# PIC18F55Q24 register map
Vendor: Microchip
Registers are 8-bit, read-write, reset 0x0 unless marked. A register's access mark holds for its fields unless they carry their own. Addresses are absolute, and some are shared; only a register's first bit layout is shown; [hi:lo] are bit positions; {n}, {i} and the like mark numbered series; 'fields as' and 'values as' point back to an identical list.

## DOS_xxxxx_pps_mid_v2_output_8bit
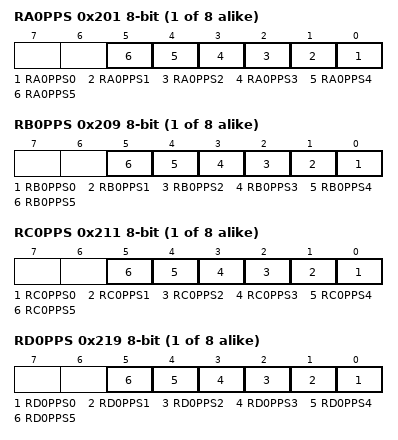
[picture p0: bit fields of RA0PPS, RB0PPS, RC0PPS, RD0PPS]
{0x201+i} RA{i}PPS (i=0..7)
  [n] RA{i}PPS{n} (n=0..5)
{0x209+i} RB{i}PPS (i=0..7)
  [n] RB{i}PPS{n} (n=0..5)
{0x211+i} RC{i}PPS (i=0..7)
  [n] RC{i}PPS{n} (n=0..5)
{0x219+i} RD{i}PPS (i=0..7)
  [n] RD{i}PPS{n} (n=0..5)
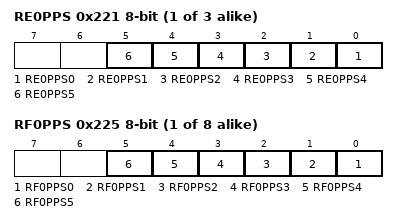
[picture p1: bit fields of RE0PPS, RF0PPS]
{0x221+i} RE{i}PPS (i=0..2)
  [n] RE{i}PPS{n} (n=0..5)
{0x225+i} RF{i}PPS (i=0..7)
  [n] RF{i}PPS{n} (n=0..5)

## DOS_xxxx_pps_mid
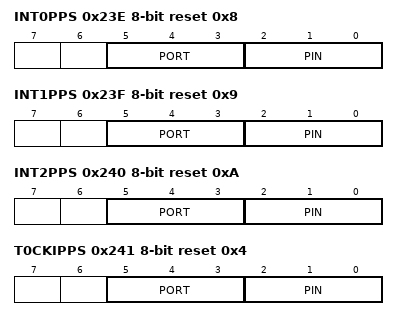
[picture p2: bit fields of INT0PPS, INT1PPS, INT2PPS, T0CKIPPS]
0x23E INT0PPS reset 0x8
  [5:3] PORT, [2:0] PIN
0x23F INT1PPS reset 0x9
  [5:3] PORT, [2:0] PIN
0x240 INT2PPS reset 0xA
  [5:3] PORT, [2:0] PIN
0x241 T0CKIPPS reset 0x4
  [5:3] PORT, [2:0] PIN
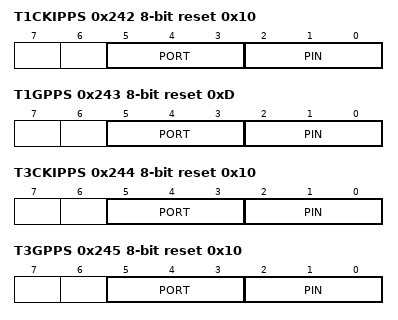
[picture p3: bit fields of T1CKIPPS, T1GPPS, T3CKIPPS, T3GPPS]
0x242 T1CKIPPS reset 0x10
  [5:3] PORT, [2:0] PIN
0x243 T1GPPS reset 0xD
  [5:3] PORT, [2:0] PIN
0x244 T3CKIPPS reset 0x10
  [5:3] PORT, [2:0] PIN
0x245 T3GPPS reset 0x10
  [5:3] PORT, [2:0] PIN
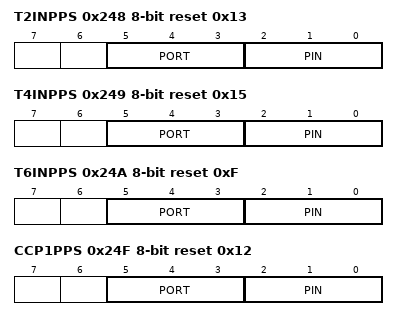
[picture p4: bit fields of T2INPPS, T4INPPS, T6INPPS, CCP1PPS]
0x248 T2INPPS reset 0x13
  [5:3] PORT, [2:0] PIN
0x249 T4INPPS reset 0x15
  [5:3] PORT, [2:0] PIN
0x24A T6INPPS reset 0xF
  [5:3] PORT, [2:0] PIN
0x24F CCP1PPS reset 0x12
  [5:3] PORT, [2:0] PIN
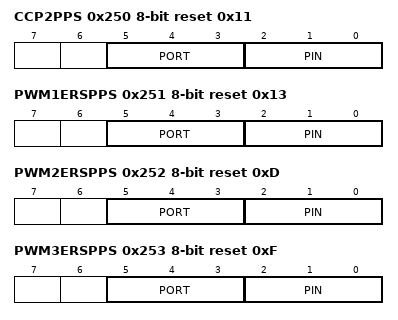
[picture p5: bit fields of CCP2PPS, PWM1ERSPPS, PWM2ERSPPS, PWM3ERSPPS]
0x250 CCP2PPS reset 0x11
  [5:3] PORT, [2:0] PIN
0x251 PWM1ERSPPS reset 0x13
  [5:3] PORT, [2:0] PIN
0x252 PWM2ERSPPS reset 0xD
  [5:3] PORT, [2:0] PIN
0x253 PWM3ERSPPS reset 0xF
  [5:3] PORT, [2:0] PIN
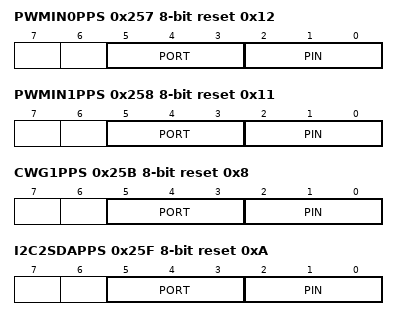
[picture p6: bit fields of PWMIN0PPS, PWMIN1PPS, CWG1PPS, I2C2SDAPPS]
0x257 PWMIN0PPS reset 0x12
  [5:3] PORT, [2:0] PIN
0x258 PWMIN1PPS reset 0x11
  [5:3] PORT, [2:0] PIN
0x25B CWG1PPS reset 0x8
  [5:3] PORT, [2:0] PIN
0x25F I2C2SDAPPS reset 0xA
  [5:3] PORT, [2:0] PIN
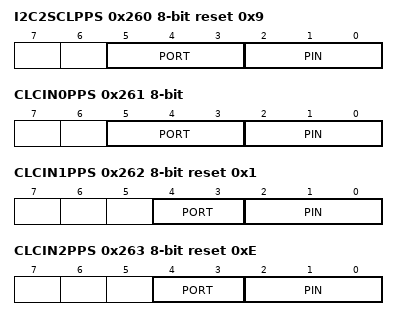
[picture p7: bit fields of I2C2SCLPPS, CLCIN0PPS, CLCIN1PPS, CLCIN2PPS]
0x260 I2C2SCLPPS reset 0x9
  [5:3] PORT, [2:0] PIN
0x261 CLCIN0PPS
  [5:3] PORT, [2:0] PIN
0x262 CLCIN1PPS reset 0x1
  [4:3] PORT, [2:0] PIN
0x263 CLCIN2PPS reset 0xE
  [4:3] PORT, [2:0] PIN
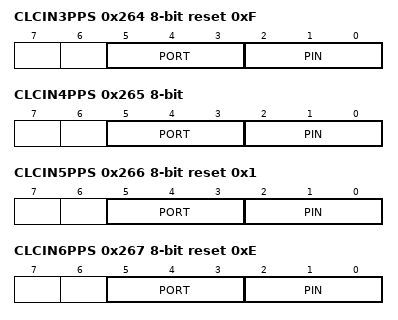
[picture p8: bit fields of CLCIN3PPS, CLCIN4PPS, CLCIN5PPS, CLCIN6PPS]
0x264 CLCIN3PPS reset 0xF
  [5:3] PORT, [2:0] PIN
0x265 CLCIN4PPS
  [5:3] PORT, [2:0] PIN
0x266 CLCIN5PPS reset 0x1
  [5:3] PORT, [2:0] PIN
0x267 CLCIN6PPS reset 0xE
  [5:3] PORT, [2:0] PIN
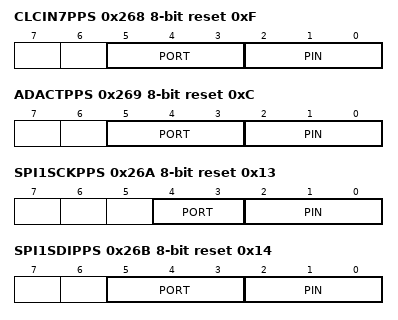
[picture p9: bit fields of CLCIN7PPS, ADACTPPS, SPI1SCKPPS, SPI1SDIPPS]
0x268 CLCIN7PPS reset 0xF
  [5:3] PORT, [2:0] PIN
0x269 ADACTPPS reset 0xC
  [5:3] PORT, [2:0] PIN
0x26A SPI1SCKPPS reset 0x13
  [4:3] PORT, [2:0] PIN
0x26B SPI1SDIPPS reset 0x14
  [5:3] PORT, [2:0] PIN
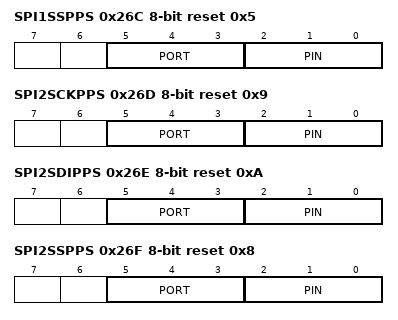
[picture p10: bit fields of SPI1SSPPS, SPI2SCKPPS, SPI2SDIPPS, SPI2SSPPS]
0x26C SPI1SSPPS reset 0x5
  [5:3] PORT, [2:0] PIN
0x26D SPI2SCKPPS reset 0x9
  [5:3] PORT, [2:0] PIN
0x26E SPI2SDIPPS reset 0xA
  [5:3] PORT, [2:0] PIN
0x26F SPI2SSPPS reset 0x8
  [5:3] PORT, [2:0] PIN
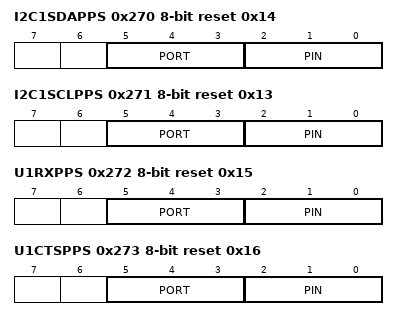
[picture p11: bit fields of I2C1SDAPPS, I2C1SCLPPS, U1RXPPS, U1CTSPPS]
0x270 I2C1SDAPPS reset 0x14
  [5:3] PORT, [2:0] PIN
0x271 I2C1SCLPPS reset 0x13
  [5:3] PORT, [2:0] PIN
0x272 U1RXPPS reset 0x15
  [5:3] PORT, [2:0] PIN
0x273 U1CTSPPS reset 0x16
  [5:3] PORT, [2:0] PIN
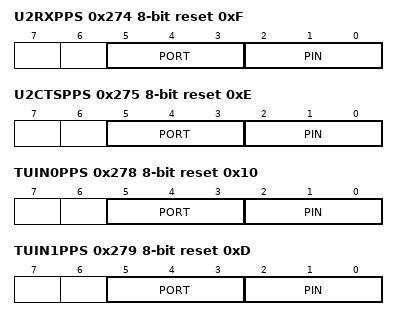
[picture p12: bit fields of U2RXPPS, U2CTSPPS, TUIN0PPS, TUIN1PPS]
0x274 U2RXPPS reset 0xF
  [5:3] PORT, [2:0] PIN
0x275 U2CTSPPS reset 0xE
  [5:3] PORT, [2:0] PIN
0x278 TUIN0PPS reset 0x10
  [5:3] PORT, [2:0] PIN
0x279 TUIN1PPS reset 0xD
  [5:3] PORT, [2:0] PIN
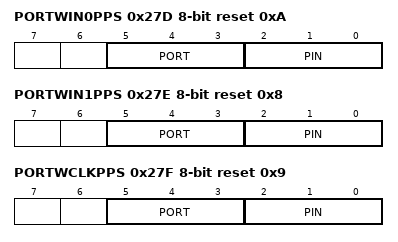
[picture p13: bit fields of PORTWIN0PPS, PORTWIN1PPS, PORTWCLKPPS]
0x27D PORTWIN0PPS reset 0xA
  [5:3] PORT, [2:0] PIN
0x27E PORTWIN1PPS reset 0x8
  [5:3] PORT, [2:0] PIN
0x27F PORTWCLKPPS reset 0x9
  [5:3] PORT, [2:0] PIN

## uart_protocol
0x2B6 U1RXB ro
  [7:0] RXB
0x2B7 U1RXCHK
  [7:0] RXCHK
0x2B8 U1TXB
  [7:0] TXB
0x2B9 U1TXCHK
  [7:0] TXCHK
0x2BA U1P1L
  [7:0] P1L
{0x2B9+2i} U1P{i}H (i=1..3)
  [0] P{i}H
0x2BC U1P2L
  [7:0] P2L
0x2BE U1P3L reset not defined — (power-on value xxxxxxxx)
  [7:0] P3L
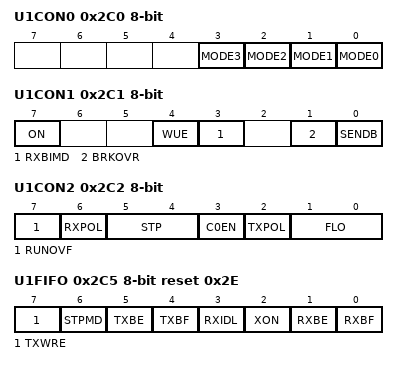
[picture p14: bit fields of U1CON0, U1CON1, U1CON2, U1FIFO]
0x2C0 U1CON0
  [n] MODE{n} (n=0..3)
0x2C1 U1CON1
  [7] ON, [4] WUE, [3] RXBIMD, [1] BRKOVR, [0] SENDB
0x2C2 U1CON2
  [7] RUNOVF, [6] RXPOL, [5:4] STP, [3] C0EN, [2] TXPOL, [1:0] FLO
0x2C3 U1BRGL
  [7:0] BRGL
0x2C4 U1BRGH
  [7:0] BRGH
0x2C5 U1FIFO reset 0x2E
  [7] TXWRE, [6] STPMD, [5] TXBE, [4] TXBF ro, [3] RXIDL ro, [2] XON ro, [1] RXBE ro, [0] RXBF ro
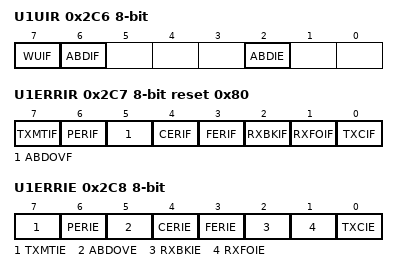
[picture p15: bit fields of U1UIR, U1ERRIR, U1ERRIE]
0x2C6 U1UIR
  [7] WUIF, [6] ABDIF, [2] ABDIE
0x2C7 U1ERRIR reset 0x80
  [7] TXMTIF, [6] PERIF, [5] ABDOVF, [4] CERIF, [3] FERIF, [2] RXBKIF, [1] RXFOIF, [0] TXCIF
0x2C8 U1ERRIE
  [7] TXMTIE, [6] PERIE, [5] ABDOVE, [4] CERIE, [3] FERIE, [2] RXBKIE, [1] RXFOIE, [0] TXCIE
0x2C9 U2RXB ro
  [7:0] RXB
0x2CB U2TXB
  [7:0] TXB
0x2CD U2P1L
  [7:0] P1L
0x2CF U2P2L
  [7:0] P2L
0x2D1 U2P3L reset not defined — (power-on value xxxxxxxx)
  [7:0] P3L
0x2D3 U2CON0
  [n] MODE{n} (n=0..3)
0x2D4 U2CON1
  [7] ON, [4] WUE, [3] RXBIMD, [1] BRKOVR, [0] SENDB
0x2D5 U2CON2
  [7] RUNOVF, [6] RXPOL, [5:4] STP, [2] TXPOL, [1:0] FLO
0x2D6 U2BRGL
  [7:0] BRGL
0x2D7 U2BRGH
  [7:0] BRGH
0x2D8 U2FIFO reset 0x2E
  fields as U1FIFO
0x2D9 U2UIR
  [7] WUIF, [6] ABDIF, [2] ABDIE
0x2DA U2ERRIR reset 0x80
  fields as U1ERRIR
0x2DB U2ERRIE
  fields as U1ERRIE
